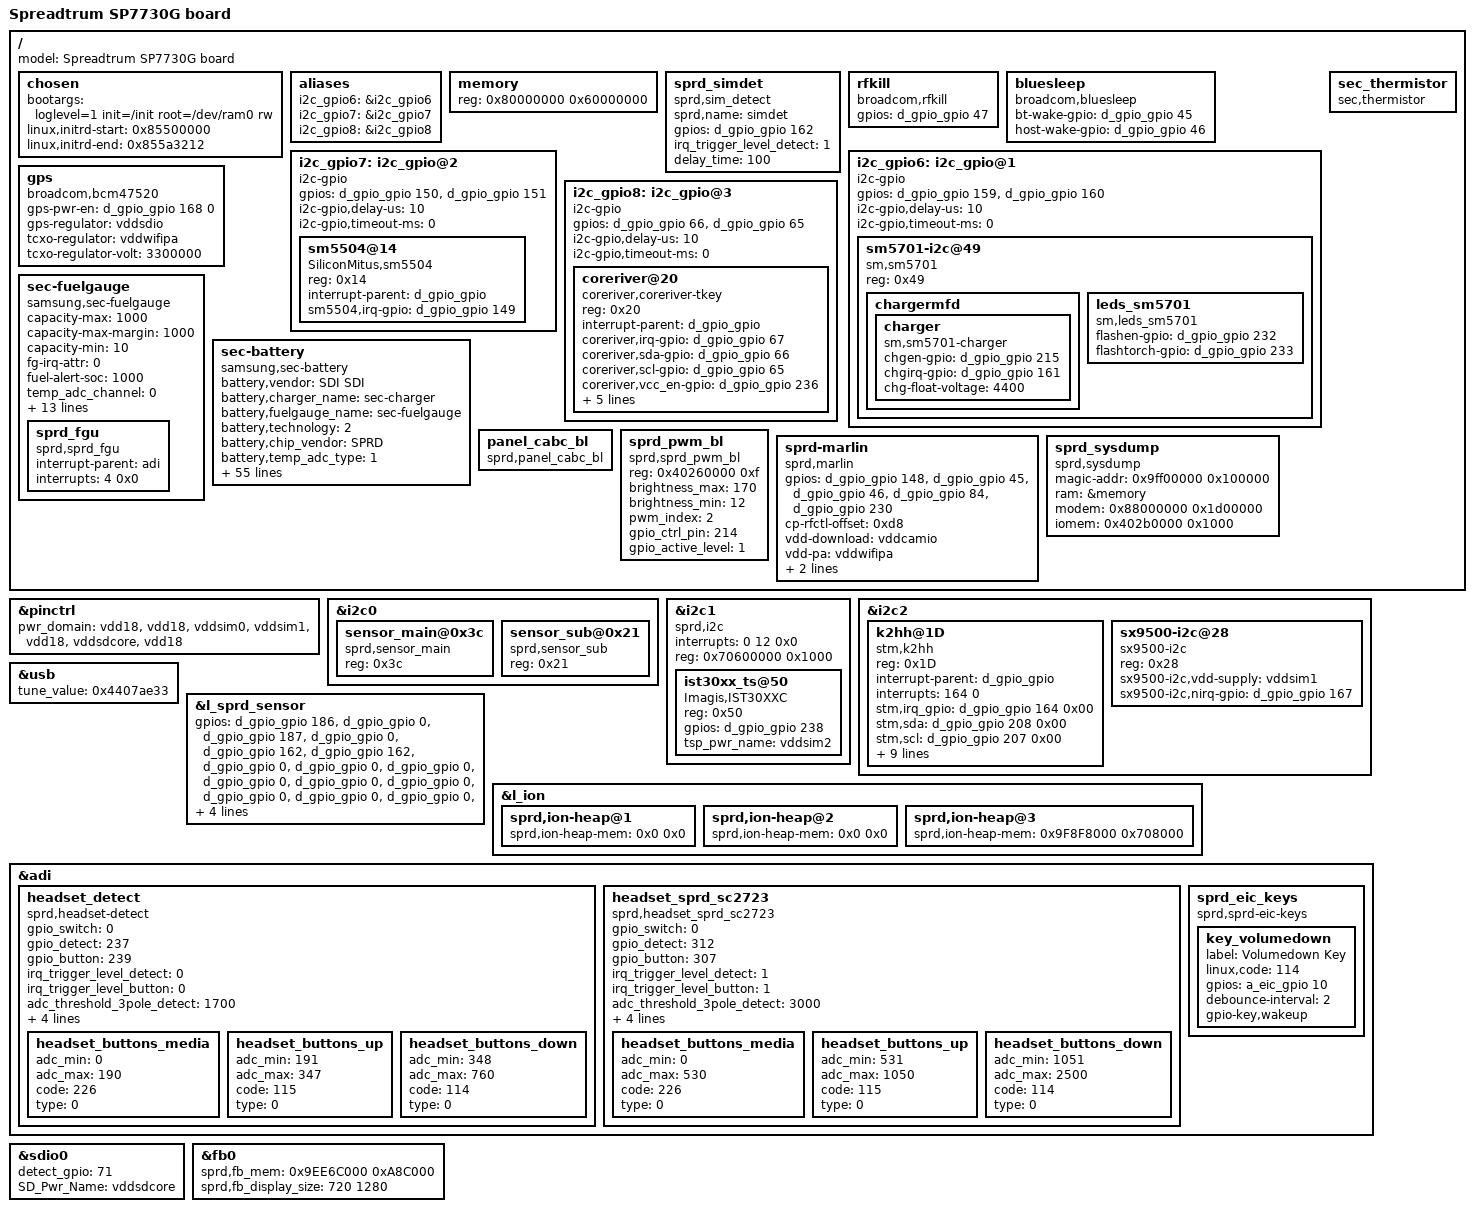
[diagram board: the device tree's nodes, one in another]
/*
 * Copyright (C) 2013 Spreadtrum Communication Incorporated
 *		http://www.spreadtrum.com/
 *
 * This program is free software; you can redistribute it and/or modify
 * it under the terms of the GNU General Public License version 2 as
 * published by the Free Software Foundation.
 */
/dts-v1/;

/* memory reserved for SMEM */
/memreserve/ 0x87800000 0x400000; /* 4M */

/* memory reserved for CPW modem */
/memreserve/ 0x88000000 0x1d00000; /* 29M */

/* memory reserved for fb */
/memreserve/ 0x9EE6C000 0xA8C000; /* 1280*720*4*3, 4K alignment */

/* memory reserved for ION */
/memreserve/ 0x9F8F8000 0x708000; /* 1280*720*4*2, 8K alignment */ 

/include/ "sprd-scx35_3.dtsi"

/ {
	model = "Spreadtrum SP7730G board";

	chosen {
		bootargs = "loglevel=1 init=/init root=/dev/ram0 rw";
		linux,initrd-start = <0x85500000>;
		linux,initrd-end   = <0x855a3212>;
	};

	aliases {
		i2c_gpio6 = &i2c_gpio6;
		i2c_gpio7 = &i2c_gpio7;
		i2c_gpio8 = &i2c_gpio8;
	};

	memory: memory {
		device_type = "memory";
		reg = <0x80000000 0x60000000>;
	};


	sprd_simdet {
		compatible = "sprd,sim_detect";
		sprd,name = "simdet";
		gpios = <&d_gpio_gpio 162 0>;
		irq_trigger_level_detect = <1>;
		delay_time = <100>;
	};

	rfkill {
		compatible = "broadcom,rfkill";
		gpios = <&d_gpio_gpio 47 0>;   /* power */
	};
	bluesleep {
		compatible = "broadcom,bluesleep";
		bt-wake-gpio = <&d_gpio_gpio 45 0>; /*GPIO_AP2BT_WAKE*/
		host-wake-gpio = <&d_gpio_gpio 46 0>; /*GPIO_BT2AP_WAKE*/
	};

i2c_gpio6: i2c_gpio@1 {
			   compatible = "i2c-gpio";
			   #address-cells = <1>;
			   #size-cells = <0>;
			   gpios = <&d_gpio_gpio 159 0 /* sda */
				   &d_gpio_gpio 160 0 >; /* scl */
			   i2c-gpio,delay-us = <10>;    /* ~100 kHz */
			   i2c-gpio,timeout-ms = <0>;
			   status = "okay";

		sm5701-i2c@49 {
			compatible = "sm,sm5701";
			reg = <0x49>;
			chargermfd {
				charger {
					compatible = "sm,sm5701-charger";
					chgen-gpio = <&d_gpio_gpio 215 0>;
					chgirq-gpio = <&d_gpio_gpio 161 0>;
					chg-float-voltage = <4400>;
				};
			};
                        leds_sm5701 {
                                        compatible = "sm,leds_sm5701";
                                        flashen-gpio = <&d_gpio_gpio 232 0>;
                                        flashtorch-gpio = <&d_gpio_gpio 233 0>;
                        };

		};
	};

i2c_gpio7: i2c_gpio@2 {
			   compatible = "i2c-gpio";
			   #address-cells = <1>;
			   #size-cells = <0>;
			   gpios = <&d_gpio_gpio 150 0 /* sda */
				   &d_gpio_gpio 151 0 >; /* scl */
			   i2c-gpio,delay-us = <10>;    /* ~100 kHz */
			   i2c-gpio,timeout-ms = <0>;

			   sm5504@14 {
				   compatible = "SiliconMitus,sm5504";
				   reg = <0x14>;
				   interrupt-parent = <&d_gpio_gpio>;
				   sm5504,irq-gpio = <&d_gpio_gpio 149 0>;
			   };
		   };
		   
i2c_gpio8: i2c_gpio@3 {
        compatible = "i2c-gpio";
        #address-cells = <1>;
        #size-cells = <0>;
        gpios = <&d_gpio_gpio 66 0 /* sda */
        &d_gpio_gpio 65 0 >; /* scl */
        i2c-gpio,delay-us = <10>;    /* ~100 kHz */
        i2c-gpio,timeout-ms = <0>;
        status = "okay";
        coreriver@20 {
                    compatible = "coreriver,coreriver-tkey";
                    reg = <0x20>;
                    interrupt-parent = <&d_gpio_gpio>;
                    coreriver,irq-gpio = <&d_gpio_gpio 67 0>;
                    coreriver,sda-gpio = <&d_gpio_gpio 66 0>;
                    coreriver,scl-gpio = <&d_gpio_gpio 65 0>;
                    coreriver,vcc_en-gpio = <&d_gpio_gpio 236 0>;
                    coreriver,fw_name = "coreriver/j33g.fw";
                    coreriver,ext_fw_name = "coreriver/j33g.fw";
                    coreriver,sensing_ch_num = <4>;
                    coreriver,tsk_ic_num = <1>; /*tc300k : 0x00, tc350k : 0x01 */
                    coreriver,firm-up; /* if, firmware auto update NOT required, comment or remove it */
                    /*tk_vdd-supply = <&tk_ldo>;*/
                };
            };

		   gps {
			   compatible = "broadcom,bcm47520";
			   gps-pwr-en = <&d_gpio_gpio 168 0>;	/*GPS_PWON*/
			   gps-regulator = "vddsdio";
			   tcxo-regulator = "vddwifipa";         /* tcxo power */
			   tcxo-regulator-volt = <3300000>;    /* 3.3V */
		   };

		   sec_thermistor {
			   compatible = "sec,thermistor";
		   };

		   sec-fuelgauge {
			   compatible = "samsung,sec-fuelgauge";
			   capacity-max = <1000>;
			   capacity-max-margin = <1000>;
			   capacity-min = <10>;
			   fg-irq-attr = <0>;
			   fuel-alert-soc = <1000>;
			   temp_adc_channel = <0>;
			   chg_bat_safety_vol = <4600>;
			   gpios = <&a_eic_gpio 0 0>;/* chg int */
			   soft_vbat_uvlo = <3050>;
			   vmode = <0>; /* 1=Voltage mode, 0=mixed mode */
			   alm_soc = <5>; /* SOC alm level %*/
			   alm_vbat = <3500>; /* Vbat alm level mV*/
			   rint = <220>; /*battery internal impedance*/
			   cnom = <3600>; /* nominal capacity in mAh */
			   rsense_real = <206>; /* sense resistor 0.1mOhm from real environment*/
			   rsense_spec = <200>; /* sense resistor 0.1mOhm from specification*/
			   relax_current = <50>; /* current for relaxation in mA (< C/20) */
			   ocv_table = <4343 100
				   4285 95
				   4231 90
				   4179 85
				   4128 80
				   4080 75
				   4035 70
				   3983 65
				   3949 60
				   3896 55
				   3861 50
				   3836 45
				   3816 40
				   3798 35
				   3785 30
				   3773 25
				   3757 20
				   3734 15
				   3694 10
				   3688 5
				   3400 0>;
sprd_fgu: sprd_fgu{
			  compatible  = "sprd,sprd_fgu";
			  interrupt-parent = <&adi>;
			  interrupts = <4 0x0>;
		  };
		   };

		   sec-battery {
			   compatible = "samsung,sec-battery";
			   battery,vendor = "SDI SDI";
			   battery,charger_name = "sec-charger";
			   battery,fuelgauge_name = "sec-fuelgauge";
			   battery,technology = <2>; /* POWER_SUPPLY_TECHNOLOGY_LION */

			   battery,chip_vendor = "SPRD";
			   battery,temp_adc_type = <1>; /* SEC_BATTERY_ADC_TYPE_AP */

			   battery,polling_time = <10 30 30 30 3600>;

			   battery,adc_check_count = <5>;

			   battery,cable_check_type = <5>; /* SEC_BATTERY_CABLE_CHECK_PSY */
			   battery,cable_source_type = <3>; /* SEC_BATTERY_CABLE_SOURCE_EXTERNAL */
			   battery,event_waiting_time = <600>;
			   battery,polling_type = <1>; /* SEC_BATTERY_MONITOR_ALARM */
			   battery,monitor_initial_count = <3>;

		battery,battery_check_type = <5>; /* SEC_BATTERY_CHECK_CHARGER */
		battery,check_count = <0>;
		battery,check_adc_max = <1440>;
		battery,check_adc_min = <0>;

		battery,ovp_uvlo_check_type = <3>; /* SEC_BATTERY_OVP_UVLO_CHGPOLLING */

		battery,thermal_source = <2>; /* SEC_BATTERY_THERMAL_SOURCE_ADC */

		battery,temp_table_adc = <501 615 738 795 846 956 1065 1088 1180 1307 1392 1477 1627 1777 1922 2098
			2144 2182 2212 2260 2302 2452 2555>;
		battery,temp_table_data = <700 650 600 580 550 500 460 450 400 350 300 250 200 150 100
			50 20 0 (-20) (-50) (-70) (-150) (-200)>;

		battery,temp_check_type = <2>; /* SEC_BATTERY_TEMP_CHECK_TEMP */
		battery,temp_check_count = <1>;
		battery,temp_high_threshold_event = <600>;
		battery,temp_high_recovery_event = <460>;
		battery,temp_low_threshold_event = <(-50)>;
		battery,temp_low_recovery_event = <0>;
		battery,temp_high_threshold_normal = <600>;
		battery,temp_high_recovery_normal = <460>;
		battery,temp_low_threshold_normal = <(-50)>;
		battery,temp_low_recovery_normal = <0>;
		battery,temp_high_threshold_lpm = <600>;
		battery,temp_high_recovery_lpm = <460>;
		battery,temp_low_threshold_lpm = <(-50)>;
		battery,temp_low_recovery_lpm = <0>;
		battery,full_check_type = <7>; /* SEC_BATTERY_FULLCHARGED_CHGPSY */
		battery,full_check_type_2nd = <3>; /* SEC_BATTERY_FULLCHARGED_TIME */
		battery,full_check_count = <1>;
		battery,chg_gpio_full_check = <0>;
		battery,chg_polarity_full_check = <1>;

		battery,full_condition_type = <13>;
		battery,full_condition_soc = <95>;
		battery,full_condition_vcell = <4200>;

		battery,recharge_check_count = <1>;
		battery,recharge_condition_type = <4>; /* SEC_BATTERY_RECHARGE_CONDITION_VCELL */
		battery,recharge_condition_soc = <95>;
		battery,recharge_condition_vcell = <4350>;

		battery,charging_total_time = <21600>;
		battery,recharging_total_time = <5400>;
		battery,charging_reset_time = <0>;

		/* Charger */
		charger,vbus_ctrl_gpio = <&d_gpio_gpio 64 0x00>;
		battery,input_current_limit = <700 460 460 700 460 700 700 460 460 700 700 700 700 460 700 300 700 700 300 700 700 460 460>;
		battery,fast_charging_current = <975 0 975 975 975 975 975 975 0 975 975 975 975 (-1) 975 975 975 975 975 975 975 0 0>;
		battery,full_check_current_1st = <175 0 175 175 175 175 175 175 0 175 175 175 175 0 175 175 175 175 175 175 175 0 0>;
		battery,full_check_current_2nd = <1800 0 1800 1800 1800 1800 1800 1800 0 1800 1800 1800 1800 0 1800 1800 1800 1800 1800 1800 1800 0 0>;
	};


		   panel_cabc_bl {
			   compatible = "sprd,panel_cabc_bl";
		   };

		   sprd_pwm_bl {
			compatible = "sprd,sprd_pwm_bl";
			reg = <0x40260000 0xf>;
			   brightness_max = <170>;
			   brightness_min = <12>;
			   pwm_index = <2>;
			   gpio_ctrl_pin = <214>;
			   gpio_active_level = <1>;
		   };

	sprd-marlin {
		compatible = "sprd,marlin";
		gpios = <&d_gpio_gpio 148 0 /*marlin gpio0 */
			&d_gpio_gpio 45 0  /*marlin gpio1 */
			&d_gpio_gpio 46 0  /*marlin gpio2 */
			&d_gpio_gpio 84 0  /*no need */
			&d_gpio_gpio 230 0>;  /*marlin reset*/
		cp-rfctl-offset = <0xd8>;  /*no need*/
		vdd-download = "vddcamio"; /*vdd 1.6v*/
		vdd-pa = "vddwifipa"; /*vdd 3.3v*/
		clk-name = "clk_aux0"; /*clk 32k*/
		sdhci-name = "sdio_wifi";
	};
	sprd_sysdump {
		compatible = "sprd,sysdump";
		magic-addr = <0x9ff00000 0x100000>;
		ram = &memory;
		modem = <0x88000000 0x1d00000>;/* modem ram*/
		iomem = <0x402b0000 0x1000>;/* pmu cfg*/
	};
};

&pinctrl {
	pwr_domain ="vdd18", /* "vdd18" */ /* VIO_2_0_ms */
			   "vdd18", /* "vdd28" */ /* VIO_2_1_ms */
			   "vddsim0",
			   "vddsim1",
			   "vdd18", /* "vddsim2" */
			   "vddsdcore",
			   "vdd18";
};

&i2c0 {
	sensor_main@0x3c {
		compatible = "sprd,sensor_main";
		reg = <0x3c>;
	};
	sensor_sub@0x21 {
		compatible = "sprd,sensor_sub";
		reg = <0x21>;
	};
};

&i2c1 { /* TSP */
		compatible = "sprd,i2c";
		interrupts = <0 12 0x0>;
		reg = <0x70600000 0x1000>;
		#address-cells = <1>;
		#size-cells = <0>;
		ist30xx_ts@50 {
		compatible = "Imagis,IST30XXC";
		reg = <0x50>;
		gpios = <&d_gpio_gpio 238 0>;
		tsp_pwr_name = "vddsim2";
		};
};

&i2c2 {
#size-cells = <0>;
	status = "okay";
	k2hh@1D {
		compatible = "stm,k2hh";
		reg = <0x1D>;
		interrupt-parent = <&d_gpio_gpio>;
		interrupts = <164 0>;
		stm,irq_gpio = <&d_gpio_gpio 164 0x00>;
		stm,sda = <&d_gpio_gpio 208 0x00>;
		stm,scl = <&d_gpio_gpio 207 0x00>;
		stm,reg_vdd-supply = <&vdd18>;
		stm,axis_map_x = <0>;
		stm,axis_map_y = <1>;
		stm,axis_map_z = <2>;
		stm,negate_x = <1>;
		stm,negate_y = <1>;
		stm,negate_z = <1>;
		stm,poll_interval = <100>;
		stm,min_interval = <2>;
	};

	sx9500-i2c@28 {
		compatible = "sx9500-i2c";
		reg = <0x28>;
		sx9500-i2c,vdd-supply = <&vddsim1>;
		sx9500-i2c,nirq-gpio = <&d_gpio_gpio 167 0x0>;
	};
};

&usb {
	tune_value = <0x4407ae33>;
};

&l_sprd_sensor {
	gpios = <&d_gpio_gpio 186 0    /* 0: main reset*/
		&d_gpio_gpio 0 0    /* 1: main powerdown*/
		&d_gpio_gpio 187 0    /* 2:sub reset*/
		&d_gpio_gpio 0 0    /* 3:sub powerdown*/
		&d_gpio_gpio 162 0     /* 4:main core voltage*/
		&d_gpio_gpio 162 0     /* 5:sub core voltage*/
		&d_gpio_gpio 0 0   /* 6:flash mode en */
		&d_gpio_gpio 0 0   /* 7:torch mode en*/
		&d_gpio_gpio 0 0   /* 8:3rd camea rst*/
		&d_gpio_gpio 0 0   /* 9:3rd camea pwdn*/
		&d_gpio_gpio 0 0   /* 10:3rd camea switch en */
		&d_gpio_gpio 0 0   /* 11:3rd camea switch mode*/
		&d_gpio_gpio 0 0   /* 12:main id*/
		&d_gpio_gpio 0 0   /* 13:main avdd voltage*/
		&d_gpio_gpio 0 0   /* 14:sub avdd voltage*/
		&d_gpio_gpio 0 0    /* 15:none used*/
		&d_gpio_gpio 0 0    /* 16:none used*/
		&d_gpio_gpio 0 0    /* 17:none used*/
		&d_gpio_gpio 0 0    /* 18:none used*/
		&d_gpio_gpio 0 0>;  /* 19:none used*/
		vdds = "vddcammot",
			"vddcama",
			"vddcamd",
			"vddcamd",               /*iovdd*/
			"vddcammot",
			"vddcama",
			"vddcamd",
			"vddcamd";             /*iovdd*/
};

&l_ion {
	sprd,ion-heap@1 {
		sprd,ion-heap-mem = <0x0 0x0>;
	};

	sprd,ion-heap@2 {
		sprd,ion-heap-mem = <0x0 0x0>;
	};

	sprd,ion-heap@3 {
		sprd,ion-heap-mem = <0x9F8F8000 0x708000>;
	};
};

&adi {
	headset_detect {
		compatible = "sprd,headset-detect";
		gpio_switch = <0>;
		gpio_detect = <237>;
		gpio_button = <239>;
		irq_trigger_level_detect = <0>;
		irq_trigger_level_button = <0>;
		adc_threshold_3pole_detect = <1700>;
		adc_threshold_4pole_detect = <2700>;
		irq_threshold_buttont = <1>;
		voltage_headmicbias = <3000000>;
		nbuttons = <3>;
		headset_buttons_media {
			adc_min = <0>;
			adc_max = <190>;
			code = <226>;
			type = <0>;
		};

		headset_buttons_up {
			adc_min = <191>;
			adc_max = <347>;
			code = <115>;
			type = <0>;
		};

		headset_buttons_down {
			adc_min = <348>;
			adc_max =<760>;
			code = <114>;
			type = <0>;
		};
	};

	headset_sprd_sc2723 {
		compatible = "sprd,headset_sprd_sc2723";
		gpio_switch = <0>;
		gpio_detect = <312>;
		gpio_button = <307>;
		irq_trigger_level_detect = <1>;
		irq_trigger_level_button = <1>;
		adc_threshold_3pole_detect = <3000>;
		adc_threshold_4pole_detect = <4500>;
		irq_threshold_buttont = <3>;
		voltage_headmicbias = <3000000>;
		nbuttons = <3>;
		headset_buttons_media {
			adc_min = <0>;
			adc_max = <530>;
			code = <226>;
			type = <0>;
		};

		headset_buttons_up {
			adc_min = <531>;
			adc_max = <1050>;
			code = <115>;
			type = <0>;
		};

		headset_buttons_down {
			adc_min = <1051>;
			adc_max =<2500>;
			code = <114>;
			type = <0>;
		};
	};


	sprd_eic_keys {
		compatible = "sprd,sprd-eic-keys";
		key_volumedown {
			label = "Volumedown Key";
			linux,code = <114>;
			gpios = <&a_eic_gpio 10 0>;
			debounce-interval = <2>;
			gpio-key,wakeup;
		};
	};
};

&sdio0 {
	detect_gpio = <71>;
	SD_Pwr_Name = "vddsdcore";
	/*_1_8V_signal_Name = "vddsdio";*/
};

&fb0 {
	sprd,fb_mem = <0x9EE6C000 0xA8C000>;
	sprd,fb_display_size = <720 1280>;
};
